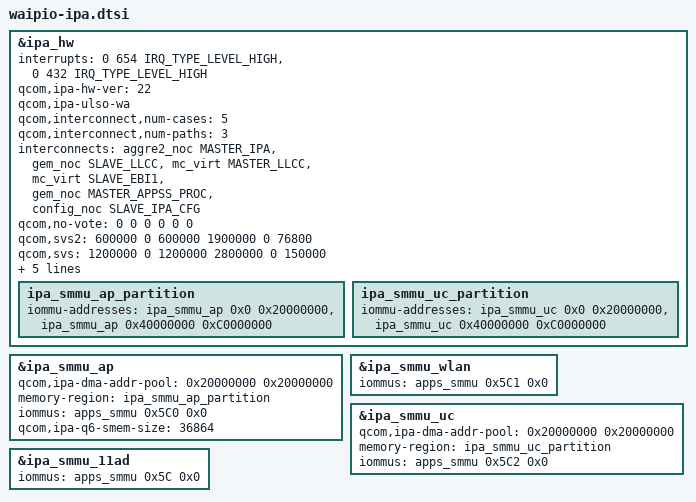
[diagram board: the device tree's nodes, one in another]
// SPDX-License-Identifier: BSD-3-Clause
/*
 * Copyright (c) Qualcomm Technologies, Inc. and/or its subsidiaries.
 */
#include "ipa.dtsi"


&ipa_hw {
	interrupts =
		<0 654 IRQ_TYPE_LEVEL_HIGH>,
		<0 432 IRQ_TYPE_LEVEL_HIGH>;
	qcom,ipa-hw-ver = <22>; /* IPA core version = IPAv5.1 */
	qcom,ipa-ulso-wa;

	/delete-property/ qcom,entire-ipa-block-size;
	/delete-property/ qcom,register-collection-on-crash;
	/delete-property/ qcom,testbus-collection-on-crash;
	/delete-property/ qcom,non-tn-collection-on-crash;

	qcom,interconnect,num-cases = <5>;
	qcom,interconnect,num-paths = <3>;
	interconnects = <&aggre2_noc MASTER_IPA &gem_noc SLAVE_LLCC>,
		<&mc_virt MASTER_LLCC &mc_virt SLAVE_EBI1>,
		<&gem_noc MASTER_APPSS_PROC &config_noc SLAVE_IPA_CFG>;
	interconnect-names = "ipa_to_llcc", "llcc_to_ebi1", "appss_to_ipa";

	/* No vote */
	qcom,no-vote =
	<0 0 0 0 0 0>;

	/* SVS2 */
	qcom,svs2 =
	<600000 0 600000 1900000 0 76800>;

	/* SVS */
	qcom,svs =
	<1200000 0 1200000 2800000 0 150000>;

	/* NOMINAL */
	qcom,nominal =
	<2400000 0 2400000 5500000 0 400000>;

	/* TURBO */
	qcom,turbo =
	<3600000 0 3600000 5500000 0 400000>;

	qcom,bus-vector-names = "MIN", "SVS2", "SVS", "NOMINAL",
		"TURBO";

	#address-cells = <1>;
	#size-cells = <1>;

	ipa_smmu_ap_partition: ipa_smmu_ap_partition {
		iommu-addresses = <&ipa_smmu_ap 0x0 0x20000000>,
			<&ipa_smmu_ap 0x40000000 0xC0000000>;
	};

	ipa_smmu_uc_partition: ipa_smmu_uc_partition {
		iommu-addresses = <&ipa_smmu_uc 0x0 0x20000000>,
			<&ipa_smmu_uc 0x40000000 0xC0000000>;
	};
};

&ipa_smmu_ap {
	/delete-property/ qcom,iommu-dma-addr-pool;
	qcom,ipa-dma-addr-pool = <0x20000000 0x20000000>;
	memory-region = <&ipa_smmu_ap_partition>;
	iommus = <&apps_smmu 0x5C0 0x0>;
	qcom,ipa-q6-smem-size = <36864>;
};

&ipa_smmu_wlan {
	iommus = <&apps_smmu 0x5C1 0x0>;
};

&ipa_smmu_uc {
	/delete-property/ qcom,iommu-dma-addr-pool;
	qcom,ipa-dma-addr-pool = <0x20000000 0x20000000>;
	memory-region = <&ipa_smmu_uc_partition>;
	iommus = <&apps_smmu 0x5C2 0x0>;
};

&ipa_smmu_11ad {
	iommus = <&apps_smmu 0x5C 0x0>;
};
